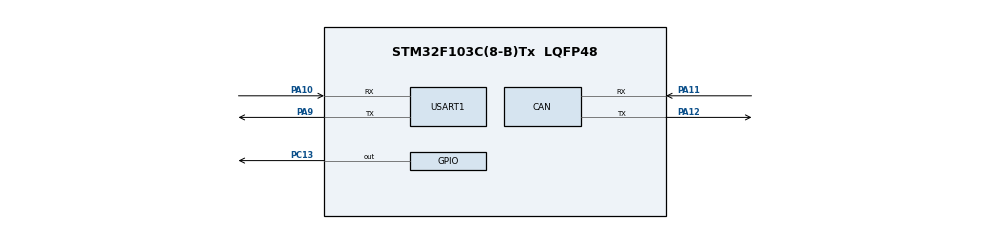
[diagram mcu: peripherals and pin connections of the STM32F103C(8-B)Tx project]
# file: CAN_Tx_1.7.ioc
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CAN.CalculateTimeBit=6000
CAN.CalculateTimeQuantum=2000.0
Mcu.Family=STM32F1
Mcu.Name=STM32F103C(8-B)Tx
Mcu.Package=LQFP48
NVIC.PriorityGroup=NVIC_PRIORITYGROUP_4
PA10.Mode=Asynchronous
PA10.Signal=USART1_RX
PA11.Mode=Master
PA11.Signal=CAN_RX
PA12.Mode=Master
PA12.Signal=CAN_TX
PA9.Mode=Asynchronous
PA9.Signal=USART1_TX
PC13-TAMPER-RTC.Signal=GPIO_Output
ProjectManager.HeapSize=0x200
ProjectManager.StackSize=0x400
ProjectManager.TargetToolchain=Makefile
RCC.APB1Freq_Value=8000000
RCC.APB2Freq_Value=8000000
USART1.VirtualMode=VM_ASYNC
VP_SYS_VS_ND.Mode=No_Debug
board=custom

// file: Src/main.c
/* USER CODE BEGIN Header */
/**
  ******************************************************************************
  * @file           : main.c
  * @brief          : Main program body
  ******************************************************************************
  * @attention
  *
  * <h2><center>&copy; Copyright (c) 2019 STMicroelectronics.
  * All rights reserved.</center></h2>
  *
  * This software component is licensed by ST under BSD 3-Clause license,
  * the "License"; You may not use this file except in compliance with the
  * License. You may obtain a copy of the License at:
  *                        opensource.org/licenses/BSD-3-Clause
  *
  ******************************************************************************
  */
/* USER CODE END Header */

#include "main.h"

CAN_HandleTypeDef hcan;

UART_HandleTypeDef huart1;

/* USER CODE BEGIN PV */
CAN_TxHeaderTypeDef   TxHeader;
CAN_RxHeaderTypeDef   RxHeader;
uint8_t               TxData[8] = {0x55, 0x55, 0x55, 0x55, 0x55, 0x55, 0x55, 0x55};
uint8_t               RxData[8];
uint32_t              TxMailbox;
/* USER CODE END PV */

void SystemClock_Config(void);
static void MX_GPIO_Init(void);
static void MX_CAN_Init(void);
static void MX_USART1_UART_Init(void);

int main(void)
{

  /* MCU Configuration--------------------------------------------------------*/

  /* Reset of all peripherals, Initializes the Flash interface and the Systick. */
  HAL_Init();

  /* Configure the system clock */
  SystemClock_Config();

  /* Initialize all configured peripherals */
  MX_GPIO_Init();
  MX_CAN_Init();
  MX_USART1_UART_Init();
  /* USER CODE BEGIN 2 */
  HAL_CAN_Start(&hcan);
  /* USER CODE END 2 */

  /* Infinite loop */
  while (1)
  {
	if (HAL_CAN_AddTxMessage(&hcan, &TxHeader, TxData, &TxMailbox) == HAL_OK) HAL_GPIO_TogglePin(GPIOC, GPIO_PIN_13);

	HAL_Delay(10);
  }
}

void SystemClock_Config(void)
{
  RCC_OscInitTypeDef RCC_OscInitStruct = {0};
  RCC_ClkInitTypeDef RCC_ClkInitStruct = {0};

  /** Initializes the CPU, AHB and APB busses clocks
  */
  RCC_OscInitStruct.OscillatorType = RCC_OSCILLATORTYPE_HSI;
  RCC_OscInitStruct.HSIState = RCC_HSI_ON;
  RCC_OscInitStruct.HSICalibrationValue = RCC_HSICALIBRATION_DEFAULT;
  RCC_OscInitStruct.PLL.PLLState = RCC_PLL_NONE;
  if (HAL_RCC_OscConfig(&RCC_OscInitStruct) != HAL_OK)
  {
    Error_Handler();
  }
  /** Initializes the CPU, AHB and APB busses clocks
  */
  RCC_ClkInitStruct.ClockType = RCC_CLOCKTYPE_HCLK|RCC_CLOCKTYPE_SYSCLK
                              |RCC_CLOCKTYPE_PCLK1|RCC_CLOCKTYPE_PCLK2;
  RCC_ClkInitStruct.SYSCLKSource = RCC_SYSCLKSOURCE_HSI;
  RCC_ClkInitStruct.AHBCLKDivider = RCC_SYSCLK_DIV1;
  RCC_ClkInitStruct.APB1CLKDivider = RCC_HCLK_DIV1;
  RCC_ClkInitStruct.APB2CLKDivider = RCC_HCLK_DIV1;

  if (HAL_RCC_ClockConfig(&RCC_ClkInitStruct, FLASH_LATENCY_0) != HAL_OK)
  {
    Error_Handler();
  }
}

static void MX_CAN_Init(void)
{

  hcan.Instance = CAN1;
  hcan.Init.Prescaler = 2;
  hcan.Init.Mode = CAN_MODE_NORMAL;
  hcan.Init.SyncJumpWidth = CAN_SJW_1TQ;
  hcan.Init.TimeSeg1 = CAN_BS1_3TQ;
  hcan.Init.TimeSeg2 = CAN_BS2_4TQ;
  hcan.Init.TimeTriggeredMode = DISABLE;
  hcan.Init.AutoBusOff = DISABLE; //enable this if no other nodes on bus
  hcan.Init.AutoWakeUp = DISABLE;
  hcan.Init.AutoRetransmission = DISABLE;
  hcan.Init.ReceiveFifoLocked = DISABLE;
  hcan.Init.TransmitFifoPriority = DISABLE;
  if (HAL_CAN_Init(&hcan) != HAL_OK)
  {
    Error_Handler();
  }
  /* USER CODE BEGIN CAN_Init 2 */
  TxHeader.StdId = 0x321; 					// CAN standard ID
  TxHeader.ExtId = 0x01; 					// CAN extended ID
  TxHeader.RTR = CAN_RTR_DATA; 				// CAN frame type
  TxHeader.IDE = CAN_ID_STD; 				// CAN ID type
  TxHeader.DLC = 8; 						// CAN frame length in bytes
  TxHeader.TransmitGlobalTime = DISABLE;	// CAN timestamp in TxData[6] and TxData[7]
  /* USER CODE END CAN_Init 2 */

}

static void MX_USART1_UART_Init(void)
{

  huart1.Instance = USART1;
  huart1.Init.BaudRate = 115200;
  huart1.Init.WordLength = UART_WORDLENGTH_8B;
  huart1.Init.StopBits = UART_STOPBITS_1;
  huart1.Init.Parity = UART_PARITY_NONE;
  huart1.Init.Mode = UART_MODE_TX_RX;
  huart1.Init.HwFlowCtl = UART_HWCONTROL_NONE;
  huart1.Init.OverSampling = UART_OVERSAMPLING_16;
  if (HAL_UART_Init(&huart1) != HAL_OK)
  {
    Error_Handler();
  }

}

static void MX_GPIO_Init(void)
{
  GPIO_InitTypeDef GPIO_InitStruct = {0};

  /* GPIO Ports Clock Enable */
  __HAL_RCC_GPIOC_CLK_ENABLE();
  __HAL_RCC_GPIOA_CLK_ENABLE();

  /*Configure GPIO pin Output Level */
  HAL_GPIO_WritePin(GPIOC, GPIO_PIN_13, GPIO_PIN_RESET);

  /*Configure GPIO pin : PC13 */
  GPIO_InitStruct.Pin = GPIO_PIN_13;
  GPIO_InitStruct.Mode = GPIO_MODE_OUTPUT_PP;
  GPIO_InitStruct.Pull = GPIO_NOPULL;
  GPIO_InitStruct.Speed = GPIO_SPEED_FREQ_LOW;
  HAL_GPIO_Init(GPIOC, &GPIO_InitStruct);

}

void Error_Handler(void)
{
}

/************************ (C) COPYRIGHT STMicroelectronics *****END OF FILE****/
